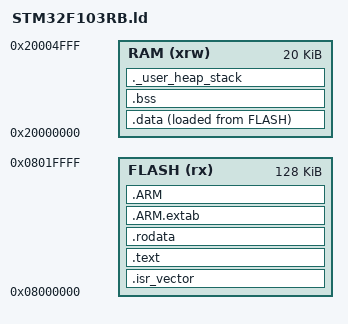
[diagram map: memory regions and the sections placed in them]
/* STM32F103RB: 128K Flash, 20K SRAM */
MEMORY
{
  FLASH (rx)  : ORIGIN = 0x08000000, LENGTH = 128K
  RAM (xrw)   : ORIGIN = 0x20000000, LENGTH = 20K
}

_estack = ORIGIN(RAM) + LENGTH(RAM);

SECTIONS
{
  .isr_vector :
  {
    . = ALIGN(4);
    KEEP(*(.isr_vector))
    . = ALIGN(4);
  } > FLASH

  .text :
  {
    . = ALIGN(4);
    *(.text)
    *(.text*)
    *(.glue_7)
    *(.glue_7t)
    *(.eh_frame)
    KEEP(*(.init))
    KEEP(*(.fini))
    . = ALIGN(4);
    _etext = .;
  } > FLASH

  .rodata :
  {
    . = ALIGN(4);
    *(.rodata)
    *(.rodata*)
    . = ALIGN(4);
  } > FLASH

  .ARM.extab :
  {
    *(.ARM.extab* .gnu.linkonce.armextab.*)
  } > FLASH

  .ARM :
  {
    __exidx_start = .;
    *(.ARM.exidx*)
    __exidx_end = .;
  } > FLASH

  _sidata = LOADADDR(.data);

  .data :
  {
    . = ALIGN(4);
    _sdata = .;
    *(.data)
    *(.data*)
    . = ALIGN(4);
    _edata = .;
  } > RAM AT > FLASH

  .bss :
  {
    . = ALIGN(4);
    _sbss = .;
    *(.bss)
    *(.bss*)
    *(COMMON)
    . = ALIGN(4);
    _ebss = .;
  } > RAM

  ._user_heap_stack :
  {
    . = ALIGN(8);
    PROVIDE(end = .);
    PROVIDE(_end = .);
    . = . + 0x200;  /* heap 512B */
    . = . + 0x400;  /* stack 1KB (minimum reservation) */
    . = ALIGN(8);
  } > RAM

  /DISCARD/ :
  {
    *(.note.GNU-stack)
  }
}
